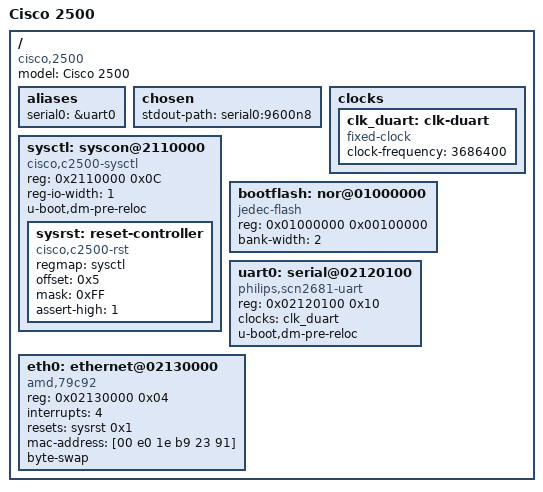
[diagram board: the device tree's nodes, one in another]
// SPDX-License-Identifier: GPL-2.0+
/*
 * Copyright (C) 2021 Celliwig
 */

/dts-v1/;

/ {
	model = "Cisco 2500";
	compatible = "cisco,2500";
	#address-cells = <1>;
	#size-cells = <1>;

	aliases {
		serial0 = &uart0;
	};

	chosen {
		stdout-path = "serial0:9600n8";
	};

	clocks {
		clk_duart: clk-duart {
			#clock-cells = <0>;
			compatible = "fixed-clock";
			clock-frequency = <3686400>;
		};
	};

	sysctl: syscon@2110000 {
		compatible = "cisco,c2500-sysctl",
			     "syscon", "simple-mfd";
		reg = <0x2110000 0x0C>;
		reg-io-width = <1>;
		u-boot,dm-pre-reloc;

		//sysclk: clock-controller {
		//	#clock-cells = <1>;
		//	compatible = "kendryte,k210-clk";
		//	clocks = <&in0>;
		//	u-boot,dm-pre-reloc;
		//};

		sysrst: reset-controller {
			compatible = "cisco,c2500-rst",
				     "syscon-reset";
			#reset-cells = <1>;
			regmap = <&sysctl>;
			offset = <0x5>;
			mask = <0xFF>;
			assert-high = <1>;
		};

		//reboot {
		//	compatible = "syscon-reboot";
		//	regmap = <&sysctl>;
		//	offset = <K210_SYSCTL_SOFT_RESET>;
		//	mask = <1>;
		//	value = <1>;
		//};
	};

	bootflash: nor@01000000 {
		compatible = "jedec-flash";
		reg = <0x01000000 0x00100000>;
		bank-width = <2>;

		status = "okay";
	};

	uart0: serial@02120100 {
		compatible = "philips,scn2681-uart";
		reg = <0x02120100 0x10>;
		//interrupts = <38>;
		clocks = <&clk_duart>;
		status = "okay";

		u-boot,dm-pre-reloc;
	};

	eth0: ethernet@02130000 {
		compatible = "amd,79c92";
		reg = <0x02130000 0x04>;
		interrupts = <4>;
		resets = <&sysrst 0x1>;				// Bit(1) controls LANCE reset
		status = "okay";

		mac-address = [00 e0 1e b9 23 91];
		byte-swap;
	};
};
